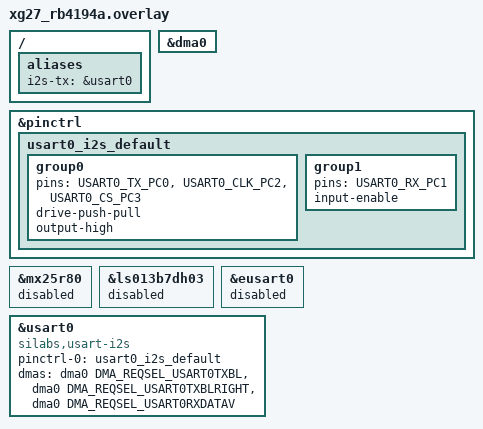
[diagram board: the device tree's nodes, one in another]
/*
 * SPDX-FileCopyrightText: Copyright (c) 2026 Silicon Laboratories Inc.
 * SPDX-License-Identifier: Apache-2.0
 *
 * xG27-RB4194A: USART0 I2S TX for samples/drivers/i2s/output.
 *
 * EXP4  PC0  TX, EXP8 PC2 BCLK, EXP10 PC3 WS.
 * Flash/display disabled (share USART0 pins).
 */

#include <zephyr/dt-bindings/pinctrl/silabs/xg27-pinctrl.h>
#include <zephyr/dt-bindings/dma/silabs/xg27-dma.h>

&dma0 {
	status = "okay";
};

/ {
	aliases {
		i2s-tx = &usart0;
		/delete-property/ spi-flash0;
	};
};

&pinctrl {
	usart0_i2s_default: usart0_i2s_default {
		group0 {
			pins = <USART0_TX_PC0>, <USART0_CLK_PC2>, <USART0_CS_PC3>;
			drive-push-pull;
			output-high;
		};

		group1 {
			pins = <USART0_RX_PC1>;
			input-enable;
		};
	};
};

&mx25r80 {
	status = "disabled";
};

&ls013b7dh03 {
	status = "disabled";
};

&eusart0 {
	status = "disabled";
};

&usart0 {
	compatible = "silabs,usart-i2s";
	#address-cells = <1>;
	#size-cells = <0>;
	status = "okay";
	pinctrl-0 = <&usart0_i2s_default>;
	pinctrl-names = "default";
	dmas = <&dma0 DMA_REQSEL_USART0TXBL>,
	       <&dma0 DMA_REQSEL_USART0TXBLRIGHT>,
	       <&dma0 DMA_REQSEL_USART0RXDATAV>;
	dma-names = "txbl", "txblright", "rx";
};
